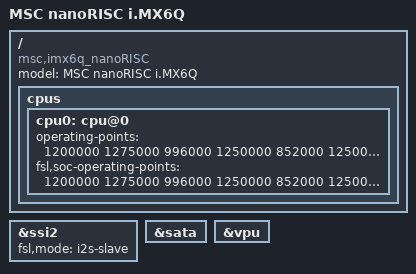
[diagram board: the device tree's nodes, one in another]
/*
 * Copyright (C) 2014 MSC Technologies, Design Center Aachen
 *
 * This program is free software; you can redistribute it and/or modify
 * it under the terms of the GNU General Public License as published by
 * the Free Software Foundation; either version 2 of the License, or
 * (at your option) any later version.

 * This program is distributed in the hope that it will be useful,
 * but WITHOUT ANY WARRANTY; without even the implied warranty of
 * MERCHANTABILITY or FITNESS FOR A PARTICULAR PURPOSE.  See the
 * GNU General Public License for more details.

 * You should have received a copy of the GNU General Public License along
 * with this program; if not, write to the Free Software Foundation, Inc.,
 * 51 Franklin Street, Fifth Floor, Boston, MA 02110-1301 USA.
 */
#include "skeleton.dtsi"
#include "imx6q-pinfunc.h"
#include "imx6q.dtsi"
#include "msc-nR-imx6qdl.dtsi"

/ {
	model = "MSC nanoRISC i.MX6Q";
	compatible = "msc,imx6q_nanoRISC", "fsl,imx6q";
	cpus {
		#address-cells = <1>;
		#size-cells = <0>;

		cpu0: cpu@0 {
			operating-points = <
				/* kHz      uV */
				1200000     1275000
				996000      1250000
				852000      1250000
				792000      1250000
				396000      975000
			>;
			fsl,soc-operating-points = <
				/* ARM kHz  SOC-PU uV */
				1200000     1275000
				996000      1250000
				852000      1250000
				792000      1250000
				396000      1175000
			>;
		};
	};
};

&ssi2 {
	fsl,mode = "i2s-slave";
	status = "okay";
};

&sata {
	status = "okay";
};

&vpu {
	status = "okay";
};
